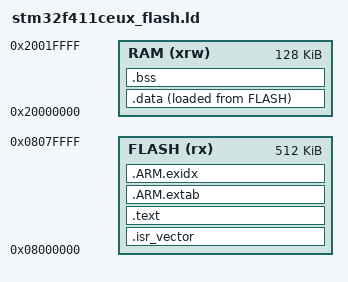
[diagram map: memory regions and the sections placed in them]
MEMORY
{
  FLASH (rx)  : ORIGIN = 0x08000000, LENGTH = 512K
  RAM (xrw)   : ORIGIN = 0x20000000, LENGTH = 128K
}
_estack = ORIGIN(RAM) + LENGTH(RAM);
ENTRY(Reset_Handler)
SECTIONS
{
  .isr_vector : { KEEP(*(.isr_vector)) } > FLASH
  .text : { *(.text*) *(.rodata*) KEEP(*(.init)) KEEP(*(.fini)) . = ALIGN(4); } > FLASH
  .ARM.extab : { *(.ARM.extab*) } > FLASH
  .ARM.exidx : { __exidx_start = .; *(.ARM.exidx*) __exidx_end = .; } > FLASH
  _sidata = LOADADDR(.data);
  .data : { . = ALIGN(4); _sdata = .; *(.data*) . = ALIGN(4); _edata = .; } > RAM AT > FLASH
  .bss : { . = ALIGN(4); _sbss = .; *(.bss*) *(COMMON) . = ALIGN(4); _ebss = .; } > RAM
  . = ALIGN(8);
  _end = .;
  ASSERT(_end + 0x600 <= ORIGIN(RAM) + LENGTH(RAM), "RAM overflow")
}
